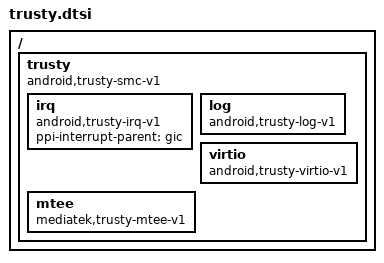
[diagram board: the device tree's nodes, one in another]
/ {
	trusty {
		compatible = "android,trusty-smc-v1";
		ranges;
		#address-cells = <2>;
		#size-cells = <2>;

		irq {
			compatible = "android,trusty-irq-v1";
			ppi-interrupt-parent = <&gic>;
		};

		log {
			compatible = "android,trusty-log-v1";
		};

		virtio {
			compatible = "android,trusty-virtio-v1";
		};

		mtee {
			compatible = "mediatek,trusty-mtee-v1";
		};

	};
};
